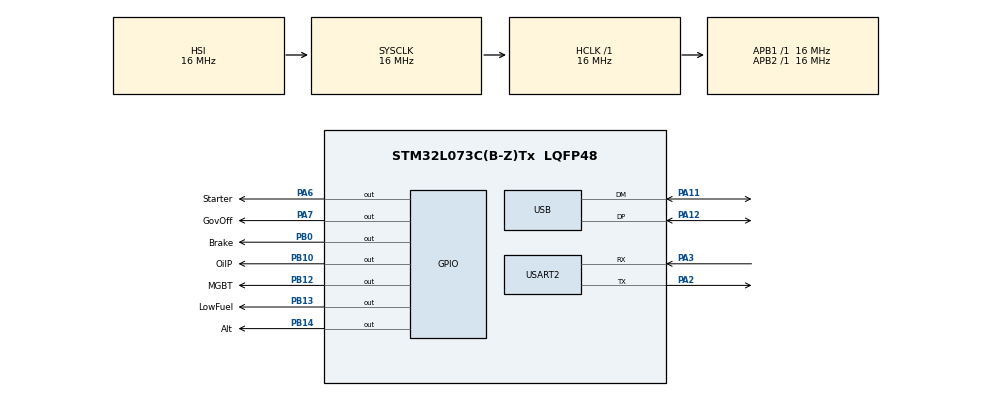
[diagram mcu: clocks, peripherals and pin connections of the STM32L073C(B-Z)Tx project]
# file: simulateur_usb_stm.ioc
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Mcu.Family=STM32L0
Mcu.Name=STM32L073C(B-Z)Tx
Mcu.Package=LQFP48
NVIC.TIM2_IRQn=true\:0\:0\:false\:false\:true\:true\:true\:true
NVIC.USB_IRQn=true\:0\:0\:false\:false\:true\:false\:true\:true
PA11.Mode=Device
PA11.Signal=USB_DM
PA12.Mode=Device
PA12.Signal=USB_DP
PA13.Mode=Serial_Wire
PA13.Signal=SYS_SWDIO
PA14.Mode=Serial_Wire
PA14.Signal=SYS_SWCLK
PA2.Mode=Asynchronous
PA2.Signal=USART2_TX
PA3.Mode=Asynchronous
PA3.Signal=USART2_RX
PA6.GPIO_Label=Starter
PA6.Signal=GPIO_Output
PA7.GPIO_Label=GovOff
PA7.Signal=GPIO_Output
PB0.GPIO_Label=Brake
PB0.Signal=GPIO_Output
PB10.GPIO_Label=OilP
PB10.Signal=GPIO_Output
PB12.GPIO_Label=MGBT
PB12.Signal=GPIO_Output
PB13.GPIO_Label=LowFuel
PB13.Signal=GPIO_Output
PB14.GPIO_Label=Alt
PB14.Signal=GPIO_Output
ProjectManager.HeapSize=0x200
ProjectManager.StackSize=0x400
ProjectManager.TargetToolchain=STM32CubeIDE
RCC.AHBFreq_Value=16000000
RCC.APB1Freq_Value=16000000
RCC.APB1TimFreq_Value=16000000
RCC.APB2Freq_Value=16000000
RCC.APB2TimFreq_Value=16000000
RCC.HCLKFreq_Value=16000000
RCC.HSE_VALUE=8000000
RCC.HSI16_VALUE=16000000
RCC.HSI48MClockSelection=RCC_USBCLKSOURCE_HSI48
RCC.HSI48_VALUE=48000000
RCC.HSI_VALUE=16000000
RCC.LSE_VALUE=32768
RCC.MSI_VALUE=2097000
RCC.PLLMUL=RCC_PLLMUL_6
RCC.SYSCLKFreq_VALUE=16000000
RCC.SYSCLKSource=RCC_SYSCLKSOURCE_HSI
RCC.VCOOutputFreq_Value=96000000
TIM2.Period=7999
TIM2.Prescaler=999
USART2.VirtualMode-Asynchronous=VM_ASYNC
USB_DEVICE.CLASS_NAME_FS=CUSTOM_HID
USB_DEVICE.CONFIGURATION_STRING_CUSTOMHID_FS=Config_BoringLights
USB_DEVICE.INTERFACE_STRING_CUSTOMHID_FS=Interface_BoringLights
USB_DEVICE.MANUFACTURER_STRING=IUT-Cachan-Vignon-Yem
USB_DEVICE.PID_CUSTOMHID_FS=0x5750
USB_DEVICE.PRODUCT_STRING_CUSTOMHID_FS=STM32-BoringLights-HID-Device
USB_DEVICE.USBD_CUSTOM_HID_REPORT_DESC_SIZE=32
USB_DEVICE.VID=0x483
USB_DEVICE.VirtualMode=CustomHid
USB_DEVICE.VirtualModeFS=Custom_Hid_FS
VP_TIM2_VS_ClockSourceINT.Mode=Internal
VP_USB_DEVICE_VS_USB_DEVICE_CUSTOM_HID_FS.Mode=CUSTOM_HID_FS
board=custom

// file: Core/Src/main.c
/* USER CODE BEGIN Header */
/**
  ******************************************************************************
  * @file           : main.c
  * @brief          : Main program body
  ******************************************************************************
  * @attention
  *
  * Copyright (c) 2024 STMicroelectronics.
  * All rights reserved.
  *
  * This software is licensed under terms that can be found in the LICENSE file
  * in the root directory of this software component.
  * If no LICENSE file comes with this software, it is provided AS-IS.
  *
  ******************************************************************************
  */
/* USER CODE END Header */
#include "main.h"
#include "usb_device.h"

/* USER CODE BEGIN Includes */
/* #include "usbd_hid.h"*/
/* USER CODE END Includes */

TIM_HandleTypeDef htim2;

UART_HandleTypeDef huart2;

/* USER CODE BEGIN PV */
extern USBD_HandleTypeDef hUsbDeviceFS;

/* USER CODE END PV */

void SystemClock_Config(void);
static void MX_GPIO_Init(void);
static void MX_TIM2_Init(void);
static void MX_USART2_UART_Init(void);

int main(void)
{

  /* MCU Configuration--------------------------------------------------------*/

  /* Reset of all peripherals, Initializes the Flash interface and the Systick. */
  HAL_Init();

  /* Configure the system clock */
  SystemClock_Config();

  /* Initialize all configured peripherals */
  MX_GPIO_Init();
  MX_USB_DEVICE_Init();
  MX_TIM2_Init();
  MX_USART2_UART_Init();
  /* USER CODE BEGIN 2 */
  HAL_TIM_Base_Start_IT(&htim2);
  /* USER CODE END 2 */

  /* Infinite loop */
  while (1)
  {

  }
}

void SystemClock_Config(void)
{
  RCC_OscInitTypeDef RCC_OscInitStruct = {0};
  RCC_ClkInitTypeDef RCC_ClkInitStruct = {0};
  RCC_PeriphCLKInitTypeDef PeriphClkInit = {0};

  /** Configure the main internal regulator output voltage
  */
  __HAL_PWR_VOLTAGESCALING_CONFIG(PWR_REGULATOR_VOLTAGE_SCALE1);

  /** Initializes the RCC Oscillators according to the specified parameters
  * in the RCC_OscInitTypeDef structure.
  */
  RCC_OscInitStruct.OscillatorType = RCC_OSCILLATORTYPE_HSI|RCC_OSCILLATORTYPE_HSI48;
  RCC_OscInitStruct.HSIState = RCC_HSI_ON;
  RCC_OscInitStruct.HSICalibrationValue = RCC_HSICALIBRATION_DEFAULT;
  RCC_OscInitStruct.HSI48State = RCC_HSI48_ON;
  RCC_OscInitStruct.PLL.PLLState = RCC_PLL_NONE;
  if (HAL_RCC_OscConfig(&RCC_OscInitStruct) != HAL_OK)
  {
    Error_Handler();
  }

  /** Initializes the CPU, AHB and APB buses clocks
  */
  RCC_ClkInitStruct.ClockType = RCC_CLOCKTYPE_HCLK|RCC_CLOCKTYPE_SYSCLK
                              |RCC_CLOCKTYPE_PCLK1|RCC_CLOCKTYPE_PCLK2;
  RCC_ClkInitStruct.SYSCLKSource = RCC_SYSCLKSOURCE_HSI;
  RCC_ClkInitStruct.AHBCLKDivider = RCC_SYSCLK_DIV1;
  RCC_ClkInitStruct.APB1CLKDivider = RCC_HCLK_DIV1;
  RCC_ClkInitStruct.APB2CLKDivider = RCC_HCLK_DIV1;

  if (HAL_RCC_ClockConfig(&RCC_ClkInitStruct, FLASH_LATENCY_0) != HAL_OK)
  {
    Error_Handler();
  }
  PeriphClkInit.PeriphClockSelection = RCC_PERIPHCLK_USART2|RCC_PERIPHCLK_USB;
  PeriphClkInit.Usart2ClockSelection = RCC_USART2CLKSOURCE_PCLK1;
  PeriphClkInit.UsbClockSelection = RCC_USBCLKSOURCE_HSI48;
  if (HAL_RCCEx_PeriphCLKConfig(&PeriphClkInit) != HAL_OK)
  {
    Error_Handler();
  }
}

static void MX_TIM2_Init(void)
{

  TIM_ClockConfigTypeDef sClockSourceConfig = {0};
  TIM_MasterConfigTypeDef sMasterConfig = {0};

  htim2.Instance = TIM2;
  htim2.Init.Prescaler = 999;
  htim2.Init.CounterMode = TIM_COUNTERMODE_UP;
  htim2.Init.Period = 7999;
  htim2.Init.ClockDivision = TIM_CLOCKDIVISION_DIV1;
  htim2.Init.AutoReloadPreload = TIM_AUTORELOAD_PRELOAD_DISABLE;
  if (HAL_TIM_Base_Init(&htim2) != HAL_OK)
  {
    Error_Handler();
  }
  sClockSourceConfig.ClockSource = TIM_CLOCKSOURCE_INTERNAL;
  if (HAL_TIM_ConfigClockSource(&htim2, &sClockSourceConfig) != HAL_OK)
  {
    Error_Handler();
  }
  sMasterConfig.MasterOutputTrigger = TIM_TRGO_RESET;
  sMasterConfig.MasterSlaveMode = TIM_MASTERSLAVEMODE_DISABLE;
  if (HAL_TIMEx_MasterConfigSynchronization(&htim2, &sMasterConfig) != HAL_OK)
  {
    Error_Handler();
  }

}

static void MX_USART2_UART_Init(void)
{

  huart2.Instance = USART2;
  huart2.Init.BaudRate = 115200;
  huart2.Init.WordLength = UART_WORDLENGTH_8B;
  huart2.Init.StopBits = UART_STOPBITS_1;
  huart2.Init.Parity = UART_PARITY_NONE;
  huart2.Init.Mode = UART_MODE_TX_RX;
  huart2.Init.HwFlowCtl = UART_HWCONTROL_NONE;
  huart2.Init.OverSampling = UART_OVERSAMPLING_16;
  huart2.Init.OneBitSampling = UART_ONE_BIT_SAMPLE_DISABLE;
  huart2.AdvancedInit.AdvFeatureInit = UART_ADVFEATURE_NO_INIT;
  if (HAL_UART_Init(&huart2) != HAL_OK)
  {
    Error_Handler();
  }

}

static void MX_GPIO_Init(void)
{
  GPIO_InitTypeDef GPIO_InitStruct = {0};

  /* GPIO Ports Clock Enable */
  __HAL_RCC_GPIOA_CLK_ENABLE();
  __HAL_RCC_GPIOB_CLK_ENABLE();

  /*Configure GPIO pin Output Level */
  HAL_GPIO_WritePin(GPIOA, Starter_Pin|GovOff_Pin, GPIO_PIN_RESET);

  /*Configure GPIO pin Output Level */
  HAL_GPIO_WritePin(GPIOB, Brake_Pin|OilP_Pin|MGBT_Pin|LowFuel_Pin
                          |Alt_Pin, GPIO_PIN_RESET);

  /*Configure GPIO pins : Starter_Pin GovOff_Pin */
  GPIO_InitStruct.Pin = Starter_Pin|GovOff_Pin;
  GPIO_InitStruct.Mode = GPIO_MODE_OUTPUT_PP;
  GPIO_InitStruct.Pull = GPIO_NOPULL;
  GPIO_InitStruct.Speed = GPIO_SPEED_FREQ_LOW;
  HAL_GPIO_Init(GPIOA, &GPIO_InitStruct);

  /*Configure GPIO pins : Brake_Pin OilP_Pin MGBT_Pin LowFuel_Pin
                           Alt_Pin */
  GPIO_InitStruct.Pin = Brake_Pin|OilP_Pin|MGBT_Pin|LowFuel_Pin
                          |Alt_Pin;
  GPIO_InitStruct.Mode = GPIO_MODE_OUTPUT_PP;
  GPIO_InitStruct.Pull = GPIO_NOPULL;
  GPIO_InitStruct.Speed = GPIO_SPEED_FREQ_LOW;
  HAL_GPIO_Init(GPIOB, &GPIO_InitStruct);

}

/* USER CODE BEGIN 4 */
void HAL_TIM_PeriodElapsedCallback(TIM_HandleTypeDef* htim)
{
	//TOGGLE_LED( GREEN );
}
/* USER CODE END 4 */

void Error_Handler(void)
{
  __disable_irq();
  while (1)
  {
  }
}
